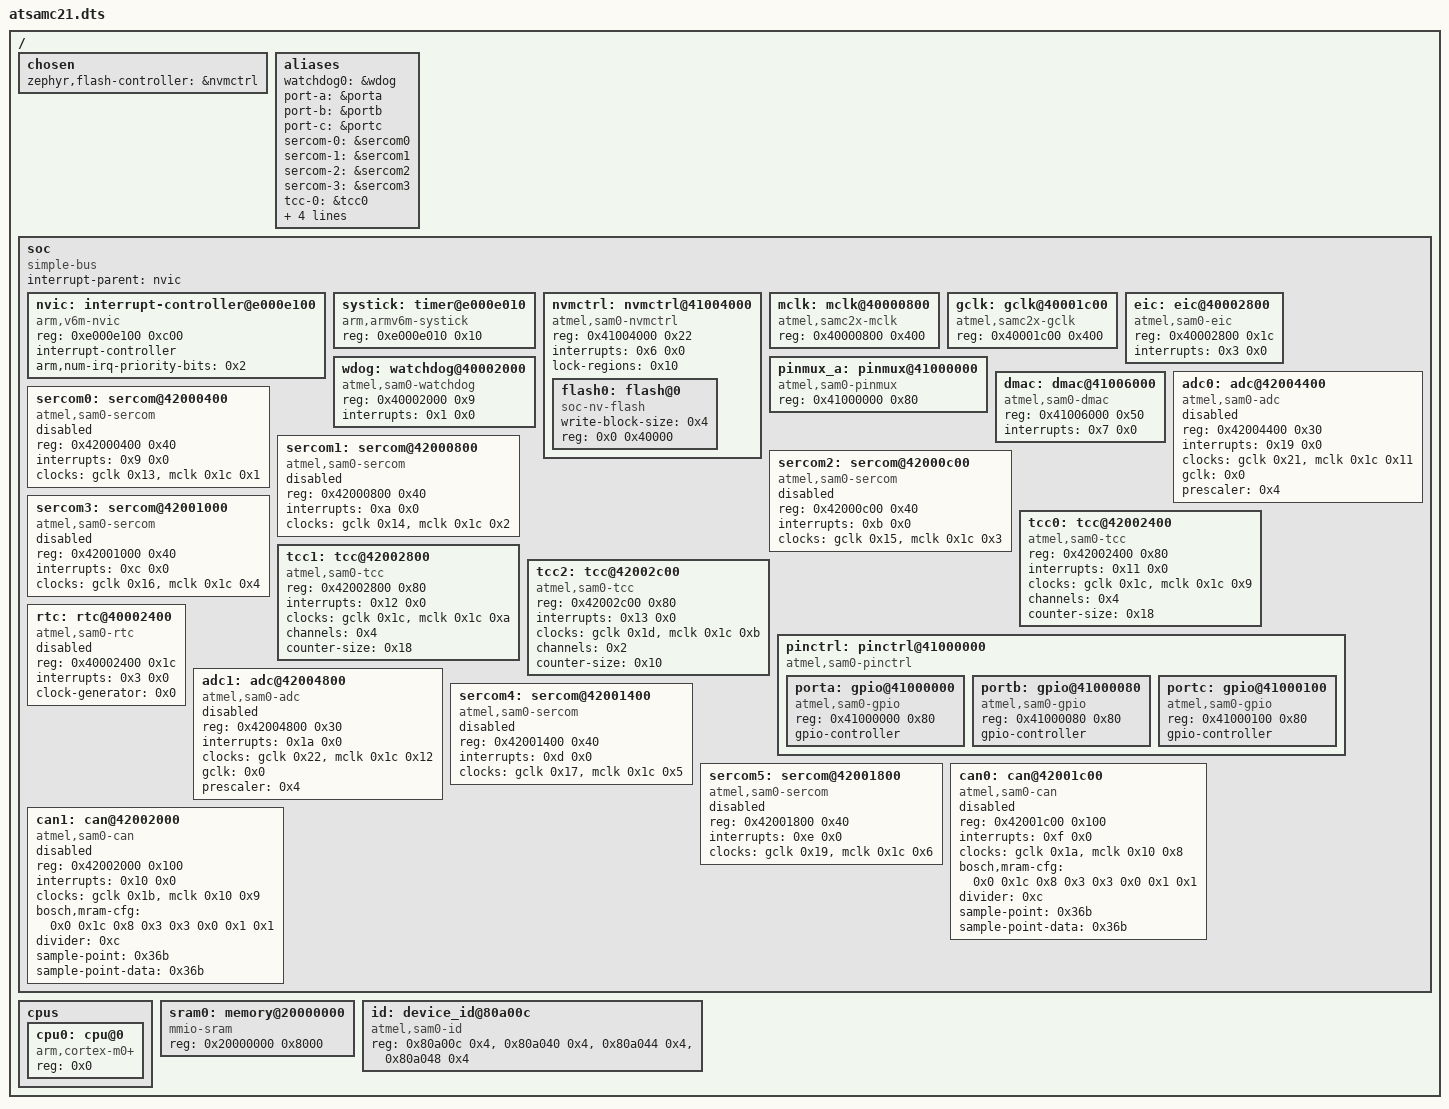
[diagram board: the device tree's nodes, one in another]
/dts-v1/;

/ {
	#address-cells = < 0x1 >;
	#size-cells = < 0x1 >;
	chosen {
		zephyr,flash-controller = &nvmctrl;
	};
	aliases {
		watchdog0 = &wdog;
		port-a = &porta;
		port-b = &portb;
		port-c = &portc;
		sercom-0 = &sercom0;
		sercom-1 = &sercom1;
		sercom-2 = &sercom2;
		sercom-3 = &sercom3;
		tcc-0 = &tcc0;
		tcc-1 = &tcc1;
		tcc-2 = &tcc2;
		sercom-4 = &sercom4;
		sercom-5 = &sercom5;
	};
	soc {
		#address-cells = < 0x1 >;
		#size-cells = < 0x1 >;
		compatible = "simple-bus";
		interrupt-parent = < &nvic >;
		ranges;
		nvic: interrupt-controller@e000e100 {
			#address-cells = < 0x1 >;
			compatible = "arm,v6m-nvic";
			reg = < 0xe000e100 0xc00 >;
			interrupt-controller;
			#interrupt-cells = < 0x2 >;
			arm,num-irq-priority-bits = < 0x2 >;
			phandle = < 0x1 >;
		};
		systick: timer@e000e010 {
			compatible = "arm,armv6m-systick";
			reg = < 0xe000e010 0x10 >;
		};
		nvmctrl: nvmctrl@41004000 {
			compatible = "atmel,sam0-nvmctrl";
			reg = < 0x41004000 0x22 >;
			interrupts = < 0x6 0x0 >;
			lock-regions = < 0x10 >;
			#address-cells = < 0x1 >;
			#size-cells = < 0x1 >;
			flash0: flash@0 {
				compatible = "soc-nv-flash";
				write-block-size = < 0x4 >;
				reg = < 0x0 0x40000 >;
			};
		};
		mclk: mclk@40000800 {
			compatible = "atmel,samc2x-mclk";
			reg = < 0x40000800 0x400 >;
			#clock-cells = < 0x2 >;
			phandle = < 0x3 >;
		};
		gclk: gclk@40001c00 {
			compatible = "atmel,samc2x-gclk";
			reg = < 0x40001c00 0x400 >;
			#clock-cells = < 0x1 >;
			phandle = < 0x2 >;
		};
		eic: eic@40002800 {
			compatible = "atmel,sam0-eic";
			reg = < 0x40002800 0x1c >;
			interrupts = < 0x3 0x0 >;
		};
		pinmux_a: pinmux@41000000 {
			compatible = "atmel,sam0-pinmux";
			reg = < 0x41000000 0x80 >;
		};
		wdog: watchdog@40002000 {
			compatible = "atmel,sam0-watchdog";
			reg = < 0x40002000 0x9 >;
			interrupts = < 0x1 0x0 >;
		};
		dmac: dmac@41006000 {
			compatible = "atmel,sam0-dmac";
			reg = < 0x41006000 0x50 >;
			interrupts = < 0x7 0x0 >;
			#dma-cells = < 0x2 >;
		};
		adc0: adc@42004400 {
			compatible = "atmel,sam0-adc";
			status = "disabled";
			reg = < 0x42004400 0x30 >;
			interrupts = < 0x19 0x0 >;
			interrupt-names = "resrdy";
			clocks = < &gclk 0x21 >, < &mclk 0x1c 0x11 >;
			clock-names = "GCLK", "MCLK";
			gclk = < 0x0 >;
			prescaler = < 0x4 >;
			#io-channel-cells = < 0x1 >;
		};
		sercom0: sercom@42000400 {
			compatible = "atmel,sam0-sercom";
			reg = < 0x42000400 0x40 >;
			interrupts = < 0x9 0x0 >;
			clocks = < &gclk 0x13 >, < &mclk 0x1c 0x1 >;
			clock-names = "GCLK", "MCLK";
			status = "disabled";
		};
		sercom1: sercom@42000800 {
			compatible = "atmel,sam0-sercom";
			reg = < 0x42000800 0x40 >;
			interrupts = < 0xa 0x0 >;
			clocks = < &gclk 0x14 >, < &mclk 0x1c 0x2 >;
			clock-names = "GCLK", "MCLK";
			status = "disabled";
		};
		sercom2: sercom@42000c00 {
			compatible = "atmel,sam0-sercom";
			reg = < 0x42000c00 0x40 >;
			interrupts = < 0xb 0x0 >;
			clocks = < &gclk 0x15 >, < &mclk 0x1c 0x3 >;
			clock-names = "GCLK", "MCLK";
			status = "disabled";
		};
		sercom3: sercom@42001000 {
			compatible = "atmel,sam0-sercom";
			reg = < 0x42001000 0x40 >;
			interrupts = < 0xc 0x0 >;
			clocks = < &gclk 0x16 >, < &mclk 0x1c 0x4 >;
			clock-names = "GCLK", "MCLK";
			status = "disabled";
		};
		tcc0: tcc@42002400 {
			compatible = "atmel,sam0-tcc";
			reg = < 0x42002400 0x80 >;
			interrupts = < 0x11 0x0 >;
			clocks = < &gclk 0x1c >, < &mclk 0x1c 0x9 >;
			clock-names = "GCLK", "MCLK";
			channels = < 0x4 >;
			counter-size = < 0x18 >;
		};
		tcc1: tcc@42002800 {
			compatible = "atmel,sam0-tcc";
			reg = < 0x42002800 0x80 >;
			interrupts = < 0x12 0x0 >;
			clocks = < &gclk 0x1c >, < &mclk 0x1c 0xa >;
			clock-names = "GCLK", "MCLK";
			channels = < 0x4 >;
			counter-size = < 0x18 >;
		};
		tcc2: tcc@42002c00 {
			compatible = "atmel,sam0-tcc";
			reg = < 0x42002c00 0x80 >;
			interrupts = < 0x13 0x0 >;
			clocks = < &gclk 0x1d >, < &mclk 0x1c 0xb >;
			clock-names = "GCLK", "MCLK";
			channels = < 0x2 >;
			counter-size = < 0x10 >;
		};
		pinctrl: pinctrl@41000000 {
			compatible = "atmel,sam0-pinctrl";
			#address-cells = < 0x1 >;
			#size-cells = < 0x1 >;
			ranges = < 0x41000000 0x41000000 0x180 >;
			porta: gpio@41000000 {
				compatible = "atmel,sam0-gpio";
				reg = < 0x41000000 0x80 >;
				gpio-controller;
				#gpio-cells = < 0x2 >;
				#atmel,pin-cells = < 0x2 >;
			};
			portb: gpio@41000080 {
				compatible = "atmel,sam0-gpio";
				reg = < 0x41000080 0x80 >;
				gpio-controller;
				#gpio-cells = < 0x2 >;
				#atmel,pin-cells = < 0x2 >;
			};
			portc: gpio@41000100 {
				compatible = "atmel,sam0-gpio";
				reg = < 0x41000100 0x80 >;
				gpio-controller;
				#gpio-cells = < 0x2 >;
				#atmel,pin-cells = < 0x2 >;
			};
		};
		rtc: rtc@40002400 {
			compatible = "atmel,sam0-rtc";
			reg = < 0x40002400 0x1c >;
			interrupts = < 0x3 0x0 >;
			clock-generator = < 0x0 >;
			status = "disabled";
		};
		adc1: adc@42004800 {
			compatible = "atmel,sam0-adc";
			status = "disabled";
			reg = < 0x42004800 0x30 >;
			interrupts = < 0x1a 0x0 >;
			interrupt-names = "resrdy";
			clocks = < &gclk 0x22 >, < &mclk 0x1c 0x12 >;
			clock-names = "GCLK", "MCLK";
			gclk = < 0x0 >;
			prescaler = < 0x4 >;
			#io-channel-cells = < 0x1 >;
		};
		sercom4: sercom@42001400 {
			compatible = "atmel,sam0-sercom";
			reg = < 0x42001400 0x40 >;
			interrupts = < 0xd 0x0 >;
			clocks = < &gclk 0x17 >, < &mclk 0x1c 0x5 >;
			clock-names = "GCLK", "MCLK";
			status = "disabled";
		};
		sercom5: sercom@42001800 {
			compatible = "atmel,sam0-sercom";
			reg = < 0x42001800 0x40 >;
			interrupts = < 0xe 0x0 >;
			clocks = < &gclk 0x19 >, < &mclk 0x1c 0x6 >;
			clock-names = "GCLK", "MCLK";
			status = "disabled";
		};
		can0: can@42001c00 {
			compatible = "atmel,sam0-can";
			reg = < 0x42001c00 0x100 >;
			interrupts = < 0xf 0x0 >;
			interrupt-names = "int0";
			clocks = < &gclk 0x1a >, < &mclk 0x10 0x8 >;
			clock-names = "GCLK", "MCLK";
			bosch,mram-cfg = < 0x0 0x1c 0x8 0x3 0x3 0x0 0x1 0x1 >;
			divider = < 0xc >;
			sample-point = < 0x36b >;
			sample-point-data = < 0x36b >;
			status = "disabled";
		};
		can1: can@42002000 {
			compatible = "atmel,sam0-can";
			reg = < 0x42002000 0x100 >;
			interrupts = < 0x10 0x0 >;
			interrupt-names = "int0";
			clocks = < &gclk 0x1b >, < &mclk 0x10 0x9 >;
			clock-names = "GCLK", "MCLK";
			bosch,mram-cfg = < 0x0 0x1c 0x8 0x3 0x3 0x0 0x1 0x1 >;
			divider = < 0xc >;
			sample-point = < 0x36b >;
			sample-point-data = < 0x36b >;
			status = "disabled";
		};
	};
	cpus {
		#address-cells = < 0x1 >;
		#size-cells = < 0x0 >;
		cpu0: cpu@0 {
			device_type = "cpu";
			compatible = "arm,cortex-m0+";
			reg = < 0x0 >;
		};
	};
	sram0: memory@20000000 {
		compatible = "mmio-sram";
		reg = < 0x20000000 0x8000 >;
	};
	id: device_id@80a00c {
		compatible = "atmel,sam0-id";
		reg = < 0x80a00c 0x4 >, < 0x80a040 0x4 >, < 0x80a044 0x4 >, < 0x80a048 0x4 >;
	};
};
